# MAILBOX register map
Vendor: Texas Instruments
Peripheral module from a debugger description file (folder am335x).
Registers are 32-bit, read-write, no defined reset value unless marked. A register's access mark holds for its fields unless they carry their own. Offsets are as the file gives them; lines under a group give offsets from that group; [hi:lo] are bit positions; {n}, {i} and the like mark numbered series; 'fields as' and 'values as' point back to an identical list; <NAME> marks a mode.

## MAILBOX
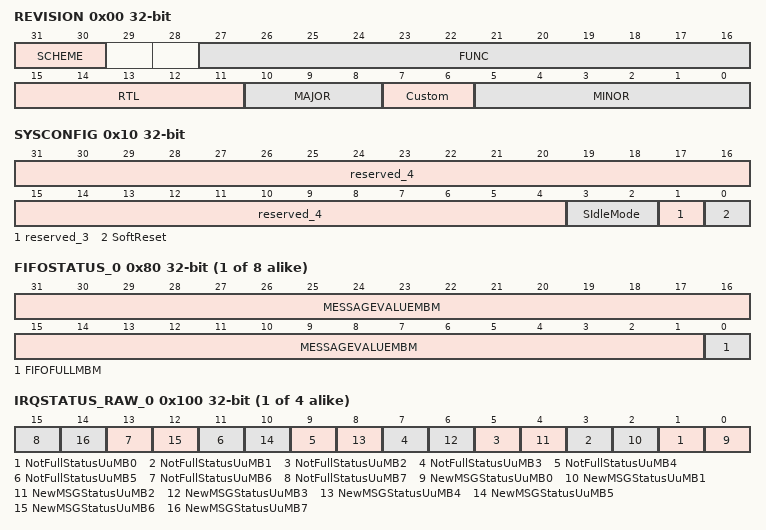
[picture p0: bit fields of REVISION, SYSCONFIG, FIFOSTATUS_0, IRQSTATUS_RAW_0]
0x00 REVISION ro — This register contains the IP revision code
  [31:30] SCHEME — Not defined yet
  [27:16] FUNC — Not defined yet
  [15:11] RTL — Not defined yet
  [10:8] MAJOR — IP-Major Revision
  [7:6] Custom — Not Defined Yet
  [5:0] MINOR — IP-Minor Revision
0x10 SYSCONFIG — This register controls the various parameters of the OCP interface
  [31:4] reserved_4 — Write 0's for future compatibility Reads returns 0
  [3:2] SIdleMode
    0=ForceIdle (An idle request is acknowledged unconditionally); 1=NoIdle (An idle request is never acknowledged); 2=SmartIdle (Acknowledgement to an idle request is given based on the internal activity of the module based on the internal activity of the module); 3=Reserved (Do not use)
  [1] reserved_3 — Write 0's for future compatibility Read returns 0
  [0] SoftReset — Software reset. This bit is automatically reset by the hardware. During reads, it always return 0
    0=Normal mode; 1=Reset (The module is reset)
{0x40+4i} MESSAGE_{i} (i=0..7) — The message register stores the next to be read message of the mailbox. Reads remove the message from the FIFO queue
  [31:0] MESSAGEVALUEMBM — Message in Mailbox. The message register stores the next to be read message of the mailbox. Reads remove the message from the FIFO queue.
{0x80+4i} FIFOSTATUS_{i} access per field (i=0..7) — The message register stores the next to be read message of the mailbox. Reads remove the message from the FIFO queue
  [31:1] MESSAGEVALUEMBM rw — Message in Mailbox. The message register stores the next to be read message of the mailbox. Reads remove the message from the FIFO queue.
  [0] FIFOFULLMBM ro — Full flag for Mailbox
    0=NotFull (Mailbox FIFO is not full); 1=Full (Mailbox FIFO is full)
{0xC0+4i} MSGSTATUS_{i} ro (i=0..7) — The message status register has the status of the messages in the mailbox
  [2:0] NBOFMSGMBM — Number of unread messages in Mailbox. Limited to four messages per mailbox.
{0x100+0x10*i} IRQSTATUS_RAW_{i} (i=0..3) — The interrupt status register has the status for each event that may be responsible for the generation of an interrupt to the corresponding user - write 1 to a given bit resets this bit. This register is mainly used for debug purpose.
  [2n+1] NotFullStatusUuMB{n} (n=0..7) — Not Full Status bit for User u, Mailbox {n}
    0=NoAction; 0=No event pending (message queue full); 1=SetEvent (Set the event (for debug)); 1=Event pending (message queue not full)
  [2n] NewMSGStatusUuMB{n} (n=0..7) — New Message Status bit for User u, Mailbox {n}
    0=NoAction; 0=No event (message) pending; 1=SetEvent (Set the event (for debug)); 1=EventPending (Event (message) pending)
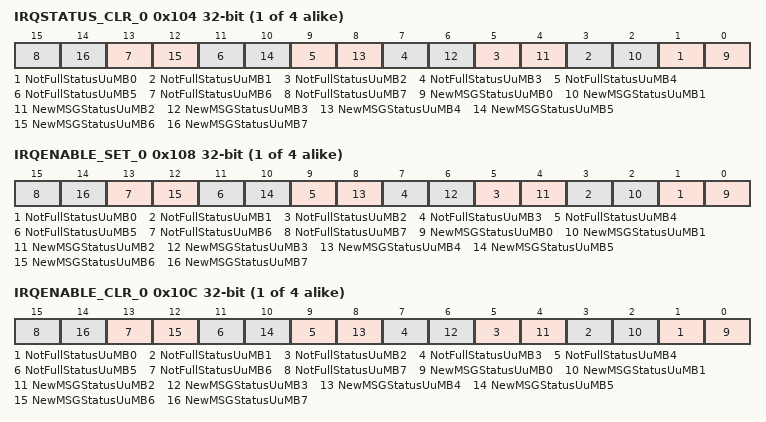
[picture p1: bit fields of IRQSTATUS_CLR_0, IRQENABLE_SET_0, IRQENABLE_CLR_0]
{0x104+0x10*i} IRQSTATUS_CLR_{i} (i=0..3) — The interrupt status register has the status combined with irq-enable for each event that may be responsible for the generation of an interrupt to the corresponding user - write 1 to a given bit resets this bit.
  fields as IRQSTATUS_RAW_0
{0x108+0x10*i} IRQENABLE_SET_{i} (i=0..3) — The interrupt enable register enables to unmask the module internal source of interrupt to the corresponding user. This register is write 1 to set.
  fields as IRQSTATUS_RAW_0
{0x10C+0x10*i} IRQENABLE_CLR_{i} (i=0..3) — The interrupt enable register enables to mask the module internal source of interrupt to the corresponding user. This register is write 1 to clear.
  fields as IRQSTATUS_RAW_0
